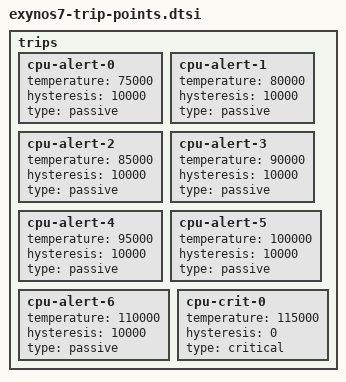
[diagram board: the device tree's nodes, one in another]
trips {
	cpu-alert-0 {
		temperature = <75000>;  
		hysteresis = <10000>;  
		type = "passive";
	};
	cpu-alert-1 {
		temperature = <80000>;  
		hysteresis = <10000>;  
		type = "passive";
	};
	cpu-alert-2 {
		temperature = <85000>;  
		hysteresis = <10000>;  
		type = "passive";
	};
	cpu-alert-3 {
		temperature = <90000>;  
		hysteresis = <10000>;  
		type = "passive";
	};
	cpu-alert-4 {
		temperature = <95000>;  
		hysteresis = <10000>;  
		type = "passive";
	};
	cpu-alert-5 {
		temperature = <100000>;  
		hysteresis = <10000>;  
		type = "passive";
	};
	cpu-alert-6 {
		temperature = <110000>;  
		hysteresis = <10000>;  
		type = "passive";
	};
	cpu-crit-0 {
		temperature = <115000>;  
		hysteresis = <0>;  
		type = "critical";
	};
};
